# AC7802x register map
Vendor: AutoChips; Series: AC78; File version: 1.0
CPU: CM0PLUS r0p1, little endian, no MPU, no FPU, VTOR, 2 interrupt priority bits
Registers are 32-bit, read-write, reset 0x0 unless marked. A register's access mark holds for its fields unless they carry their own. Offsets are from the block's base; [hi:lo] are bit positions.

## EFLASH — Embedded Flash
Base 0x40002000
0x00 UKR reset not defined — Key sequence register
  [31:0] KEY — Key sequence value
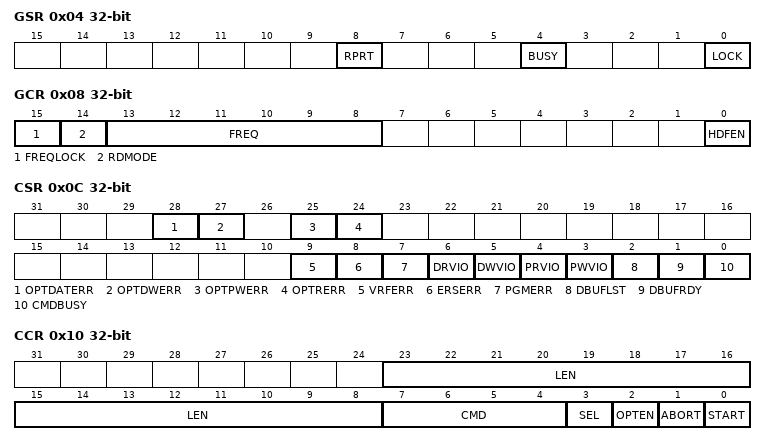
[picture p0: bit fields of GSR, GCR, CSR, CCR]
0x04 GSR (reset mask 0x10) — Global status register
  [8] RPRT ro — Read protection status
    0=Not read protected; 1=Read protected
  [4] BUSY ro — Busy status of the eflash controller
    0=not busy; 1=busy
  [0] LOCK — Lock status of the write function of the eflash controller all registers
    0=unlocked; 1=locked
0x08 GCR (reset mask 0x2000) — Global control register
  [15] FREQLOCK — Lock control of the FREQ and RDMODE register
    0=unlocked; 1=locked
  [14] RDMODE — Read speed divide 2 mode
    0=Flash controller frequency not divide 2; 1=Flash controller frequency divide 2
  [13:8] FREQ — eFlash controller frequency value
  [0] HDFEN — Enable generate hardfault violation read Protect rules
    0=disable; 1=enable
0x0C CSR (reset mask 0x4) — Command Status Register
  [28] OPTDATERR ro — Option page data verify error status
    0=Option page data verify has no error; 1=Option page data verify has error
  [27] OPTDWERR ro — Option page D-Flash write protection verify error status
    0=Option page D-Flash write protection verify has no error; 1=Option page D-Flash write protection verify has error
  [25] OPTPWERR ro — Option page P-Flash write protection verify error status
    0=Option page P-Flash write protection verify has no error; 1=Option page P-Flash write protection verify has error
  [24] OPTRERR ro — Option page read protection verify error status
    0=Option page read protection verify has no error; 1=Option page read protection verify has error
  [9] VRFERR ro — Verify command error status
    0=Verify command has no error; 1=Verify command has error
  [8] ERSERR ro — Erase command error status
    0=Erase command has no error; 1=Erase command has error
  [7] PGMERR ro — Program command error status
    0=Program command has no error; 1=Program command has error
  [6] DRVIO — D-Flash read protection rule violation status
    0=D-Flash has no read protection error; 1=D-Flash has read protection error
  [5] DWVIO — D-Flash write protection rule violation status
    0=D-Flash has no write protection error; 1=D-Flash has write protection error
  [4] PRVIO — P-Flash read protection rule violation status
    0=P-Flash has no read protection error; 1=P-Flash has read protection error
  [3] PWVIO — P-Flash write protection rule violation status
    0=P-Flash has no write protection error; 1=P-Flash has write protection error
  [2] DBUFLST ro — Command data buffer last status
    0=Not last data; 1=Last data
  [1] DBUFRDY ro — Command data buffer write ready status
    0=Data buffer not ready; 1=Data buffer ready
  [0] CMDBUSY ro — Command busy status
    0=idle; 1=busy
0x10 CCR reset not defined — Command Control Register
  [23:8] LEN — Program/verify length
  [7:4] CMD — Flash command type
  [3] SEL — Mass command operation zone select
    0=Mass command in P-Flash; 1=Mass command in D-Flash
  [2] OPTEN — Option page operation command enable control
    0=Disable; 1=Enable
  [1] ABORT — Command abort control
    0=Abort command; 1=No abort command
  [0] START — Command start control
    0=No trigger command execute; 1=Trigger command execute
0x14 CAR reset not defined — Command Address Register
  [31:0] ADDR
0x18 CDR reset not defined — Command Data Register
  [31:0] DATA
0x1C DMR reset not defined — Data Mask Register
  [3:0] DATAMASK
0x40 PWPR0 ro reset not defined — P-Flash Write protect status register 0
  [31:0] PWPR0 — P-Flash write protection bit status for page 0 - 31
0x44 PWPR1 ro reset not defined — P-Flash Write protect status register 1
  [31:0] PWPR1 — P-Flash write protection bit status for page 32 - 63
0x48 DWPR ro reset not defined — D-Flash Write protect status register
  [31:0] DWPR — D-Flash write protection bit status
